# apollo3p register map
Vendor: Ambiq Micro; Series: Apollo; File version: 1.0
CPU: CM4 r1p0, little endian, MPU, FPU, I-cache, D-cache, VTOR, ITCM, DTCM, 3 interrupt priority bits, 0 interrupts
Registers are 32-bit, read-write, reset 0x0 unless marked. A register's access mark holds for its fields unless they carry their own. Offsets are from the block's base; [hi:lo] are bit positions; {n}, {i} and the like mark numbered series; 'fields as' and 'values as' point back to an identical list.

## CTIMER (part 3 of 3) — Counter/Timer
Base 0x40008000
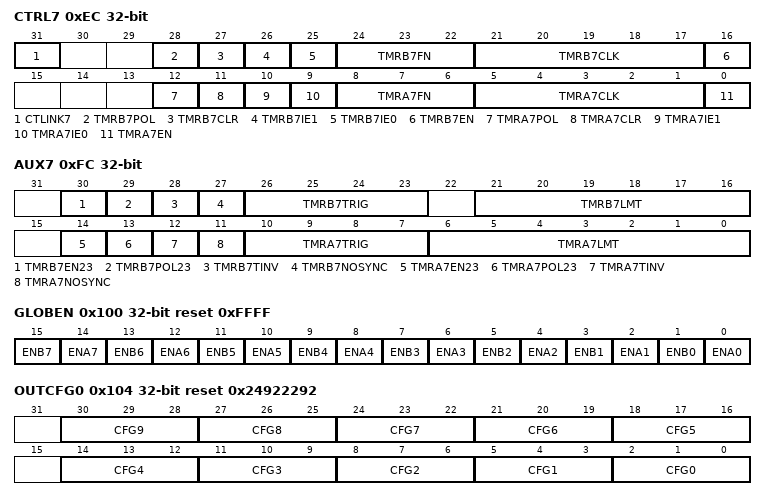
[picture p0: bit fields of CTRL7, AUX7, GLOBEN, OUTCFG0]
0xEC CTRL7 — This register holds the control bit fields for both halves of timer 7.
  [31] CTLINK7 — Counter/Timer A7/B7 Link bit.
    0=TWO_16BIT_TIMERS (Use A7/B7 timers as two independent 16-bit timers (default).); 1=32BIT_TIMER (Link A7/B7 timers into a single 32-bit timer.)
  [28] TMRB7POL — Counter/Timer B7 output polarity.
    0=NORMAL (The polarity of the TMRPINB7 pin is the same as the timer output.); 1=INVERTED (The polarity of the TMRPINB7 pin is the inverse of the timer output.)
  [27] TMRB7CLR — Counter/Timer B7 Clear bit.
    0=RUN (Allow counter/timer B7 to run); 1=CLEAR (Holds counter/timer B7 at 0x0000.)
  [26] TMRB7IE1 — Counter/Timer B7 Interrupt Enable bit for COMPR1.
    0=DIS (Disable counter/timer B7 from generating an interrupt based on COMPR1.); 1=EN (Enable counter/timer B7 to generate an interrupt based on COMPR1.)
  [25] TMRB7IE0 — Counter/Timer B7 Interrupt Enable bit for COMPR0.
    0=DIS (Disable counter/timer B7 from generating an interrupt based on COMPR0.); 1=EN (Enable counter/timer B7 to generate an interrupt based on COMPR0)
  [24:22] TMRB7FN — Counter/Timer B7 Function Select.
    0=SINGLECOUNT (Single count (output toggles and sticks). Count to CMPR0B7, stop.); 1=REPEATEDCOUNT (Repeated count (periodic 1-clock-cycle-wide pulses). Count to CMPR0B7, restart.); 2=PULSE_ONCE (Pulse once (aka one-shot). Count to CMPR0B7, assert, count to CMPR1B7, deassert, stop.); 3=PULSE_CONT (Pulse continuously. Count to CMPR0B7, assert, count to CMPR1B7, deassert, restart.); 4=SINGLEPATTERN; 5=REPEATPATTERN (Repeated pattern.); 6=CONTINUOUS (Continuous run (aka Free Run). Count continuously.); 7=ALTPWN (Alternate PWM)
  [21:17] TMRB7CLK — Counter/Timer B7 Clock Select.
    0=TMRPIN (Clock source is TMRPINB.); 1=HFRC_DIV4 (Clock source is the HFRC / 4); 2=HFRC_DIV16 (Clock source is HFRC / 16); 3=HFRC_DIV256 (Clock source is HFRC / 256); 4=HFRC_DIV1024 (Clock source is HFRC / 1024); 5=HFRC_DIV4K (Clock source is HFRC / 4096); 6=XT (Clock source is the XT (uncalibrated).); 7=XT_DIV2 (Clock source is XT / 2); 8=XT_DIV16 (Clock source is XT / 16); 9=XT_DIV128 (Clock source is XT / 128); 10=LFRC_DIV2 (Clock source is LFRC / 2); 11=LFRC_DIV32 (Clock source is LFRC / 32); 12=LFRC_DIV1K (Clock source is LFRC / 1024); 13=LFRC (Clock source is LFRC); 14=RTC_100HZ (Clock source is 100 Hz from the current RTC oscillator.); 15=HCLK_DIV4 (Clock source is HCLK / 4 (note: this clock is only available when MCU is in active mode)); 16=XT_DIV4 (Clock source is XT / 4); 17=XT_DIV8 (Clock source is XT / 8); 18=XT_DIV32 (Clock source is XT / 32); 20=CTMRA7 (Clock source is CTIMERA7 OUT.); 21=CTMRA2 (Clock source is CTIMERA2 OUT.); 22=CTMRB2 (Clock source is CTIMERB2 OUT.); 23=CTMRA0 (Clock source is CTIMERA0 OUT.); 24=CTMRB0 (Clock source is CTIMERB0 OUT.); 25=CTMRB1 (Clock source is CTIMERB1 OUT.); 26=CTMRB3 (Clock source is CTIMERB3 OUT.); 27=CTMRB4 (Clock source is CTIMERB4 OUT.); 28=CTMRB5 (Clock source is CTIMERB5 OUT.); 29=BUCKBLE (Clock source is BLE buck converter TON pulses.); 30=BUCKB (Clock source is Memory buck converter TON pulses.); 31=BUCKA (Clock source is CPU buck converter TON pulses.)
  [16] TMRB7EN — Counter/Timer B7 Enable bit.
    0=DIS (Counter/Timer B7 Disable.); 1=EN (Counter/Timer B7 Enable.)
  [12] TMRA7POL — Counter/Timer A7 output polarity.
    0=NORMAL (The polarity of the TMRPINA7 pin is the same as the timer output.); 1=INVERTED (The polarity of the TMRPINA7 pin is the inverse of the timer output.)
  [11] TMRA7CLR — Counter/Timer A7 Clear bit.
    0=RUN (Allow counter/timer A7 to run); 1=CLEAR (Holds counter/timer A7 at 0x0000.)
  [10] TMRA7IE1 — Counter/Timer A7 Interrupt Enable bit based on COMPR1.
    0=DIS (Disable counter/timer A7 from generating an interrupt based on COMPR1.); 1=EN (Enable counter/timer A7 to generate an interrupt based on COMPR1.)
  [9] TMRA7IE0 — Counter/Timer A7 Interrupt Enable bit based on COMPR0.
    0=DIS (Disable counter/timer A7 from generating an interrupt based on COMPR0.); 1=EN (Enable counter/timer A7 to generate an interrupt based on COMPR0.)
  [8:6] TMRA7FN — Counter/Timer A7 Function Select.
    0=SINGLECOUNT (Single count (output toggles and sticks). Count to CMPR0A7, stop.); 1=REPEATEDCOUNT (Repeated count (periodic 1-clock-cycle-wide pulses). Count to CMPR0A7, restart.); 2=PULSE_ONCE (Pulse once (aka one-shot). Count to CMPR0A7, assert, count to CMPR1A7, deassert, stop.); 3=PULSE_CONT (Pulse continuously. Count to CMPR0A7, assert, count to CMPR1A7, deassert, restart.); 4=SINGLEPATTERN; 5=REPEATPATTERN (Repeated pattern.); 6=CONTINUOUS (Continuous run (aka Free Run). Count continuously.); 7=ALTPWN (Alternate PWM)
  [5:1] TMRA7CLK — Counter/Timer A7 Clock Select.
    0=TMRPIN (Clock source is TMRPINA.); 1=HFRC_DIV4 (Clock source is the HFRC / 4); 2=HFRC_DIV16 (Clock source is HFRC / 16); 3=HFRC_DIV256 (Clock source is HFRC / 256); 4=HFRC_DIV1024 (Clock source is HFRC / 1024); 5=HFRC_DIV4K (Clock source is HFRC / 4096); 6=XT (Clock source is the XT (uncalibrated).); 7=XT_DIV2 (Clock source is XT / 2); 8=XT_DIV16 (Clock source is XT / 16); 9=XT_DIV128 (Clock source is XT / 128); 10=LFRC_DIV2 (Clock source is LFRC / 2); 11=LFRC_DIV32 (Clock source is LFRC / 32); 12=LFRC_DIV1K (Clock source is LFRC / 1024); 13=LFRC (Clock source is LFRC); 14=RTC_100HZ (Clock source is 100 Hz from the current RTC oscillator.); 15=HCLK_DIV4 (Clock source is HCLK / 4 (note: this clock is only available when MCU is in active mode)); 16=XT_DIV4 (Clock source is XT / 4); 17=XT_DIV8 (Clock source is XT / 8); 18=XT_DIV32 (Clock source is XT / 32); 20=CTMRB7 (Clock source is CTIMERB7 OUT.); 21=CTMRA2 (Clock source is CTIMERA2 OUT.); 22=CTMRB2 (Clock source is CTIMERB2 OUT.); 23=CTMRA0 (Clock source is CTIMERA0 OUT.); 24=CTMRB0 (Clock source is CTIMERB0 OUT.); 25=CTMRB1 (Clock source is CTIMERB1 OUT.); 26=CTMRB3 (Clock source is CTIMERB3 OUT.); 27=CTMRB4 (Clock source is CTIMERB4 OUT.); 28=CTMRB5 (Clock source is CTIMERB5 OUT.); 29=BUCKBLE (Clock source is BLE buck converter TON pulses.); 30=BUCKB (Clock source is Memory buck converter TON pulses.); 31=BUCKA (Clock source is CPU buck converter TON pulses.)
  [0] TMRA7EN — Counter/Timer A7 Enable bit.
    0=DIS (Counter/Timer A7 Disable.); 1=EN (Counter/Timer A7 Enable.)
0xFC AUX7 — Control bit fields for both halves of timer 0.
  [30] TMRB7EN23 — Counter/Timer B7 Upper compare enable.
    1=DIS (Disable enhanced functions.); 0=EN (Enable enhanced functions.)
  [29] TMRB7POL23 — Upper output polarity
    0=NORM (Upper output normal polarity); 1=INV (Upper output inverted polarity.)
  [28] TMRB7TINV — Counter/Timer B7 Invert on trigger.
    0=DIS (Disable invert on trigger); 1=EN (Enable invert on trigger)
  [27] TMRB7NOSYNC — Source clock synchronization control.
    0=DIS (Synchronization on source clock); 1=NOSYNC (No synchronization on source clock)
  [26:23] TMRB7TRIG — Counter/Timer B7 Trigger Select.
    0=DIS (Trigger source is disabled.); 1=A7OUT (Trigger source is CTIMERA7 OUT.); 2=B3OUT (Trigger source is CTIMERB3 OUT.); 3=A3OUT (Trigger source is CTIMERA3 OUT.); 4=A5OUT (Trigger source is CTIMERA5 OUT.); 5=B5OUT (Trigger source is CTIMERB5 OUT.); 6=A2OUT (Trigger source is CTIMERA2 OUT.); 7=B2OUT (Trigger source is CTIMERB2 OUT.); 8=B3OUT2 (Trigger source is CTIMERB3 OUT2.); 9=A3OUT2 (Trigger source is CTIMERA3 OUT2.); 10=A2OUT2 (Trigger source is CTIMERA2 OUT2.); 11=B2OUT2 (Trigger source is CTIMERB2 OUT2.); 12=A6OUT2DUAL (Trigger source is CTIMERA6 OUT2, dual edge.); 13=A7OUT2DUAL (Trigger source is CTIMERA7 OUT2, dual edge.); 14=B1OUT2DUAL (Trigger source is CTIMERB1 OUT2, dual edge.); 15=A1OUT2DUAL (Trigger source is CTIMERA1 OUT2, dual edge.)
  [21:16] TMRB7LMT — Counter/Timer B7 Pattern Limit Count.
  [14] TMRA7EN23 — Counter/Timer A7 Upper compare enable.
    values as TMRB7EN23
  [13] TMRA7POL23 — Counter/Timer A7 Upper output polarity
    values as TMRB7POL23
  [12] TMRA7TINV — Counter/Timer A7 Invert on trigger.
    values as TMRB7TINV
  [11] TMRA7NOSYNC — Source clock synchronization control.
    values as TMRB7NOSYNC
  [10:7] TMRA7TRIG — Counter/Timer A7 Trigger Select.
    0=DIS (Trigger source is disabled.); 1=B7OUT (Trigger source is CTIMERB7 OUT.); 2=B3OUT (Trigger source is CTIMERB3 OUT.); 3=A3OUT (Trigger source is CTIMERA3 OUT.); 4=A1OUT (Trigger source is CTIMERA1 OUT.); 5=B1OUT (Trigger source is CTIMERB1 OUT.); 6=A4OUT (Trigger source is CTIMERA4 OUT.); 7=B4OUT (Trigger source is CTIMERB4 OUT.); 8=B3OUT2 (Trigger source is CTIMERB3 OUT2.); 9=A3OUT2 (Trigger source is CTIMERA3 OUT2.); 10=A2OUT2 (Trigger source is CTIMERA2 OUT2.); 11=B2OUT2 (Trigger source is CTIMERB2 OUT2.); 12=A6OUT2DUAL (Trigger source is CTIMERA6 OUT2, dual edge.); 13=A5OUT2DUAL (Trigger source is CTIMERA5 OUT2, dual edge.); 14=B4OUT2DUAL (Trigger source is CTIMERB4 OUT2, dual edge.); 15=A4OUT2DUAL (Trigger source is CTIMERA4 OUT2, dual edge.)
  [6:0] TMRA7LMT — Counter/Timer A7 Pattern Limit Count.
0x100 GLOBEN reset 0xFFFF — Alternate enables for all CTIMERs.
  [all] fields
    1=LCO (Use local enable.); 0=DIS (Disable CTIMER.)
  [15] ENB7 — Alternate enable for B7.
  [2n] ENA{n} (n=0..7) — Alternate enable for A{n}
  [13] ENB6 — Alternate enable for B6
  [11] ENB5 — Alternate enable for B5
  [9] ENB4 — Alternate enable for B4
  [7] ENB3 — Alternate enable for B3.
  [5] ENB2 — Alternate enable for B2
  [3] ENB1 — Alternate enable for B1
  [1] ENB0 — Alternate enable for B0
0x104 OUTCFG0 reset 0x24922292 — Pad output configuration 0.
  [30:28] CFG9 — Pad output 9 configuration
    7=A7OUT2 (Output is A7OUT2.); 6=A6OUT2 (Output is A6OUT2.); 5=B0OUT (Output is B0OUT.); 4=A4OUT (Output is A4OUT.); 3=A2OUT (Output is A2OUT.); 2=A2OUT2 (Output is A2OUT2); 1=ONE (Force output to 1.); 0=ZERO (Force output to 0)
  [27:25] CFG8 — Pad output 8 configuration
    7=A7OUT2 (Output is A7OUT2.); 6=A6OUT2 (Output is A6OUT2.); 5=B6OUT (Output is B6OUT.); 4=A4OUT2 (Output is A4OUT2.); 3=A3OUT2 (Output is A3OUT.); 2=A2OUT (Output is A2OUT); 1=ONE (Force output to 1.); 0=ZERO (Force output to 0)
  [24:22] CFG7 — Pad output 7 configuration
    7=A7OUT2 (Output is A7OUT2.); 6=A6OUT2 (Output is A6OUT2.); 5=A7OUT (Output is A7OUT.); 4=B5OUT (Output is B5OUT.); 3=B1OUT (Output is B1OUT.); 2=B1OUT2 (Output is B1OUT2); 1=ONE (Force output to 1.); 0=ZERO (Force output to 0)
  [21:19] CFG6 — Pad output 6 configuration
    7=A7OUT2 (Output is A7OUT2.); 6=A6OUT2 (Output is A6OUT2.); 5=B7OUT (Output is B7OUT.); 4=B5OUT2 (Output is B5OUT2.); 3=A1OUT (Output is A1OUT.); 2=B1OUT (Output is B1OUT); 1=ONE (Force output to 1.); 0=ZERO (Force output to 0)
  [18:16] CFG5 — Pad output 5 configuration
    7=A7OUT2 (Output is A7OUT2.); 6=A6OUT2 (Output is A6OUT2.); 5=A7OUT (Output is A7OUT.); 4=B6OUT (Output is A5OUT.); 3=A1OUT (Output is A1OUT.); 2=A1OUT2 (Output is A1OUT2); 1=ONE (Force output to 1.); 0=ZERO (Force output to 0)
  [14:12] CFG4 — Pad output 4 configuration
    7=A7OUT2 (Output is A7OUT2.); 6=A6OUT2 (Output is A6OUT2.); 5=B5OUT (Output is B5OUT.); 4=A5OUT2 (Output is A5OUT2.); 3=A2OUT2 (Output is A2OUT2.); 2=A1OUT (Output is A1OUT); 1=ONE (Force output to 1.); 0=ZERO (Force output to 0)
  [11:9] CFG3 — Pad output 3 configuration
    7=A7OUT2 (Output is A7OUT2.); 6=A6OUT2 (Output is A6OUT2.); 5=A6OUT (Output is A6OUT.); 4=A1OUT (Output is A1OUT.); 3=B0OUT (Output is B0OUT.); 2=B0OUT2 (Output is B0OUT2); 1=ONE (Force output to 1.); 0=ZERO (Force output to 0)
  [8:6] CFG2 — Pad output 2 configuration
    7=A7OUT2 (Output is A7OUT2.); 6=A6OUT2 (Output is A6OUT2.); 5=A7OUT (Output is A7OUT.); 4=B6OUT2 (Output is B6OUT2.); 3=B1OUT2 (Output is B1OUT2.); 2=B0OUT (Output is B0OUT); 1=ONE (Force output to 1.); 0=ZERO (Force output to 0)
  [5:3] CFG1 — Pad output 1 configuration
    7=A7OUT2 (Output is A7OUT2.); 6=A6OUT2 (Output is A6OUT2.); 5=B7OUT2 (Output is B7OUT2.); 4=A5OUT (Output is A5OUT.); 3=A0OUT (Output is A0OUT.); 2=A0OUT2 (Output is A0OUT2); 1=ONE (Force output to 1.); 0=ZERO (Force output to 0)
  [2:0] CFG0 — Pad output 0 configuration
    7=A7OUT2 (Output is A7OUT2.); 6=A6OUT2 (Output is A6OUT2.); 5=A6OUT (Output is A6OUT.); 4=A5OUT2 (Output is A5OUT2.); 3=B2OUT2 (Output is B2OUT2.); 2=A0OUT (Output is A0OUT); 1=ONE (Force output to 1.); 0=ZERO (Force output to 0)
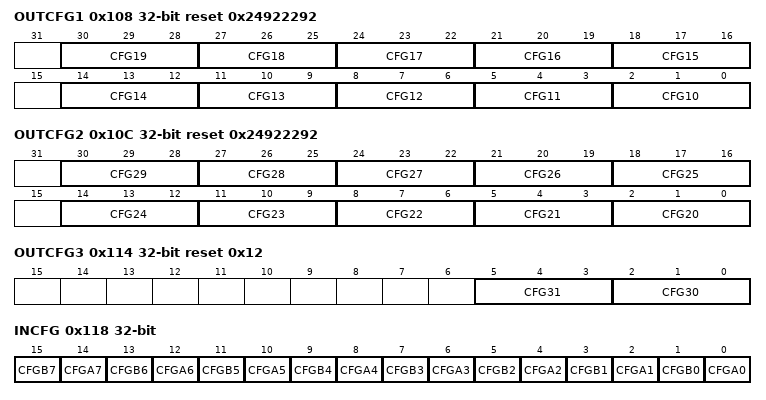
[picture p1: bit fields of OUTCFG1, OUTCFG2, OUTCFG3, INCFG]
0x108 OUTCFG1 reset 0x24922292 — Pad output configuration 1.
  [30:28] CFG19 — Pad output 19 configuration
    7=A7OUT2 (Output is A7OUT2.); 6=A6OUT2 (Output is A6OUT2.); 5=B1OUT2 (Output is B1OUT2.); 4=B4OUT (Output is B4OUT.); 3=A2OUT (Output is A2OUT.); 2=B4OUT2 (Output is B4OUT2); 1=ONE (Force output to 1.); 0=ZERO (Force output to 0)
  [27:25] CFG18 — Pad output 18 configuration
    7=A7OUT2 (Output is A7OUT2.); 6=A6OUT2 (Output is A6OUT2.); 5=A3OUT2 (Output is A3OUT2.); 4=A0OUT (Output is A0OUT.); 3=B0OUT (Output is B0OUT.); 2=B4OUT (Output is B4OUT); 1=ONE (Force output to 1.); 0=ZERO (Force output to 0)
  [24:22] CFG17 — Pad output 17 configuration
    7=A7OUT2 (Output is A7OUT2.); 6=A6OUT2 (Output is A6OUT2.); 5=A1OUT2 (Output is A1OUT2.); 4=A4OUT (Output is A4OUT.); 3=B7OUT (Output is B7OUT.); 2=A4OUT2 (Output is A4OUT2); 1=ONE (Force output to 1.); 0=ZERO (Force output to 0)
  [21:19] CFG16 — Pad output 16 configuration
    7=A7OUT2 (Output is A7OUT2.); 6=A6OUT2 (Output is A6OUT2.); 5=B3OUT2 (Output is B3OUT2.); 4=A0OUT2 (Output is A0OUT2.); 3=A0OUT (Output is A0OUT.); 2=A4OUT (Output is A4OUT); 1=ONE (Force output to 1.); 0=ZERO (Force output to 0)
  [18:16] CFG15 — Pad output 15 configuration
    7=A7OUT2 (Output is A7OUT2.); 6=A6OUT2 (Output is A6OUT2.); 5=A4OUT2 (Output is A4OUT2.); 4=A7OUT (Output is A7OUT.); 3=B3OUT (Output is B3OUT.); 2=B3OUT2 (Output is B3OUT2); 1=ONE (Force output to 1.); 0=ZERO (Force output to 0)
  [14:12] CFG14 — Pad output 14 configuration
    7=A7OUT2 (Output is A7OUT2.); 6=A6OUT2 (Output is A6OUT2.); 5=A7OUT (Output is A7OUT.); 4=B7OUT2 (Output is B7OUT2.); 3=B1OUT (Output is B1OUT.); 2=B3OUT (Output is B3OUT); 1=ONE (Force output to 1.); 0=ZERO (Force output to 0)
  [11:9] CFG13 — Pad output 13 configuration
    7=A7OUT2 (Output is A7OUT2.); 6=A6OUT2 (Output is A6OUT2.); 5=B4OUT2 (Output is B4OUT2.); 4=A6OUT (Output is A6OUT.); 3=A3OUT (Output is A3OUT.); 2=A3OUT2 (Output is A3OUT2); 1=ONE (Force output to 1.); 0=ZERO (Force output to 0)
  [8:6] CFG12 — Pad output 12 configuration
    7=A7OUT2 (Output is A7OUT2.); 6=A6OUT2 (Output is A6OUT2.); 5=B6OUT2 (Output is B6OUT2.); 4=B0OUT2 (Output is B0OUT2.); 3=B1OUT (Output is B1OUT.); 2=A3OUT (Output is A3OUT); 1=ONE (Force output to 1.); 0=ZERO (Force output to 0)
  [5:3] CFG11 — Pad output 11 configuration
    7=A7OUT2 (Output is A7OUT2.); 6=A6OUT2 (Output is A6OUT2.); 5=B5OUT2 (Output is B5OUT2.); 4=B4OUT (Output is B4OUT.); 3=B2OUT (Output is B2OUT.); 2=B2OUT2 (Output is B2OUT2); 1=ONE (Force output to 1.); 0=ZERO (Force output to 0)
  [2:0] CFG10 — Pad output 10 configuration
    7=A7OUT2 (Output is A7OUT2.); 6=A6OUT2 (Output is A6OUT2.); 5=A6OUT (Output is A6OUT.); 4=B4OUT2 (Output is B4OUT2.); 3=B3OUT2 (Output is B3OUT2.); 2=B2OUT (Output is B2OUT); 1=ONE (Force output to 1.); 0=ZERO (Force output to 0)
0x10C OUTCFG2 reset 0x24922292 — Pad output configuration 2.
  [30:28] CFG29 — Pad output 29 configuration
    7=A7OUT2 (Output is A7OUT2.); 6=A6OUT2 (Output is A6OUT2.); 5=A3OUT2 (Output is A3OUT2.); 4=A7OUT (Output is A7OUT.); 3=A1OUT (Output is A1OUT.); 2=B5OUT2 (Output is B5OUT2); 1=ONE (Force output to 1.); 0=ZERO (Force output to 0)
  [27:25] CFG28 — Pad output 28 configuration
    7=A7OUT2 (Output is A7OUT2.); 6=A6OUT2 (Output is A6OUT2.); 5=B0OUT2 (Output is B0OUT2.); 4=A5OUT2 (Output is A5OUT2.); 3=A3OUT (Output is A3OUT.); 2=A7OUT (Output is A7OUT); 1=ONE (Force output to 1.); 0=ZERO (Force output to 0)
  [24:22] CFG27 — Pad output 27 configuration
    7=A7OUT2 (Output is A7OUT2.); 6=A6OUT2 (Output is A6OUT2.); 5=B2OUT2 (Output is B2OUT2.); 4=B6OUT (Output is B6OUT.); 3=A1OUT (Output is A1OUT.); 2=B6OUT2 (Output is B6OUT2); 1=ONE (Force output to 1.); 0=ZERO (Force output to 0)
  [21:19] CFG26 — Pad output 26 configuration
    7=A7OUT2 (Output is A7OUT2.); 6=A6OUT2 (Output is A6OUT2.); 5=A1OUT2 (Output is A1OUT2.); 4=A5OUT (Output is A5OUT.); 3=B2OUT (Output is B2OUT.); 2=B6OUT (Output is B6OUT); 1=ONE (Force output to 1.); 0=ZERO (Force output to 0)
  [18:16] CFG25 — Pad output 25 configuration
    7=A7OUT2 (Output is A7OUT2.); 6=A6OUT2 (Output is A6OUT2.); 5=A2OUT2 (Output is A2OUT2.); 4=A6OUT (Output is A6OUT.); 3=B2OUT (Output is B2OUT.); 2=B4OUT2 (Output is B4OUT2); 1=ONE (Force output to 1.); 0=ZERO (Force output to 0)
  [14:12] CFG24 — Pad output 24 configuration
    7=A7OUT2 (Output is A7OUT2.); 6=A6OUT2 (Output is A6OUT2.); 5=B1OUT2 (Output is B1OUT2.); 4=A1OUT (Output is A1OUT.); 3=A2OUT (Output is A2OUT.); 2=A6OUT (Output is A6OUT); 1=ONE (Force output to 1.); 0=ZERO (Force output to 0)
  [11:9] CFG23 — Pad output 23 configuration
    7=A7OUT2 (Output is A7OUT2.); 6=A6OUT2 (Output is A6OUT2.); 5=B0OUT2 (Output is B0OUT2.); 4=A5OUT (Output is A5OUT.); 3=A7OUT (Output is A7OUT.); 2=B5OUT2 (Output is B5OUT2); 1=ONE (Force output to 1.); 0=ZERO (Force output to 0)
  [8:6] CFG22 — Pad output 22 configuration
    7=A7OUT2 (Output is A7OUT2.); 6=A6OUT2 (Output is A6OUT2.); 5=A2OUT2 (Output is A2OUT2.); 4=A1OUT (Output is A1OUT.); 3=A6OUT (Output is A6OUT.); 2=B5OUT (Output is B5OUT); 1=ONE (Force output to 1.); 0=ZERO (Force output to 0)
  [5:3] CFG21 — Pad output 21 configuration
    7=A7OUT2 (Output is A7OUT2.); 6=A6OUT2 (Output is A6OUT2.); 5=A0OUT2 (Output is A0OUT2.); 4=B5OUT (Output is B5OUT.); 3=A1OUT (Output is A1OUT.); 2=A5OUT2 (Output is A5OUT2); 1=ONE (Force output to 1.); 0=ZERO (Force output to 0)
  [2:0] CFG20 — Pad output 20 configuration
    7=A7OUT2 (Output is A7OUT2.); 6=A6OUT2 (Output is A6OUT2.); 5=B2OUT2 (Output is B2OUT2.); 4=A1OUT2 (Output is A1OUT2.); 3=A1OUT (Output is A1OUT.); 2=A5OUT (Output is A5OUT); 1=ONE (Force output to 1.); 0=ZERO (Force output to 0)
0x114 OUTCFG3 reset 0x12 — Pad output configuration 3.
  [5:3] CFG31 — Pad output 31 configuration
    7=A7OUT2 (Output is A7OUT2.); 6=A6OUT2 (Output is A6OUT2.); 5=B3OUT2 (Output is B3OUT2.); 4=B7OUT (Output is B7OUT.); 3=A6OUT (Output is A6OUT.); 2=B7OUT2 (Output is B7OUT2); 1=ONE (Force output to 1.); 0=ZERO (Force output to 0)
  [2:0] CFG30 — Pad output 30 configuration
    7=A7OUT2 (Output is A7OUT2.); 6=A6OUT2 (Output is A6OUT2.); 5=A0OUT2 (Output is A0OUT2.); 4=A4OUT2 (Output is A4OUT2.); 3=B3OUT (Output is B3OUT.); 2=B7OUT (Output is B7OUT); 1=ONE (Force output to 1.); 0=ZERO (Force output to 0)
0x118 INCFG — Pad input configuration.
  [2n+1] CFGB{n} (n=0..7) — CTIMER B{n} input configuration
    1=CT{4n+3} (Input is CT{4n+3}); 0=CT{4n+2} (Input is CT{4n+2})
  [2n] CFGA{n} (n=0..7) — CTIMER A{n} input configuration
    1=CT{4n+1} (Input is CT{4n+1}); 0=CT{4n} (Input is CT{4n})
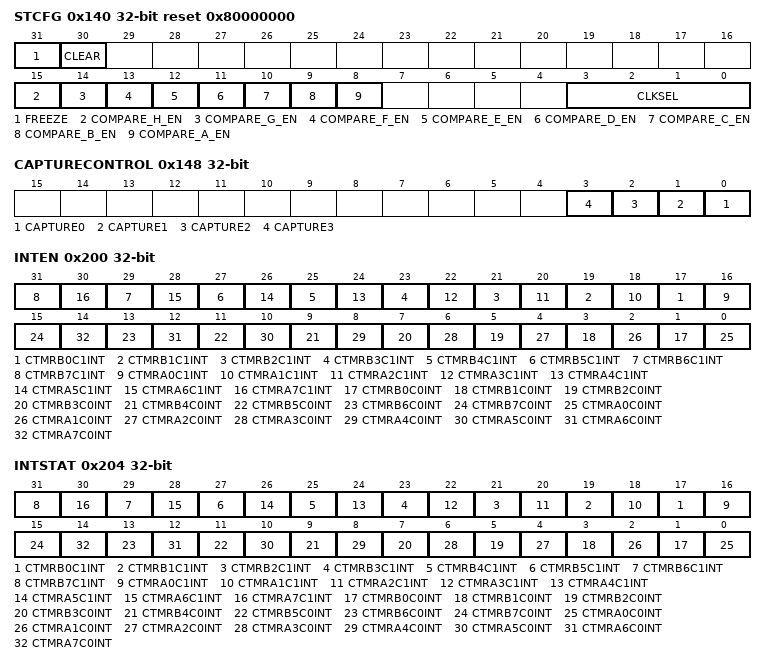
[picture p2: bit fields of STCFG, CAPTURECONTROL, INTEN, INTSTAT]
0x140 STCFG reset 0x80000000 — The STIMER Configuration Register contains the software control for selecting the clock divider and source feeding the system timer.
  [31] FREEZE — Set this bit to one to freeze the clock input to the COUNTER register. Once frozen, the value can be safely written from the MCU. Unfreeze to resume.
    0=THAW (Let the COUNTER register run on its input clock.); 1=FREEZE (Stop the COUNTER register for loading.)
  [30] CLEAR — Set this bit to one to clear the System Timer register. If this bit is set to '1', the system timer register will stay cleared. It needs to be set to '0' for the system timer to start running.
    0=RUN (Let the COUNTER register run on its input clock.); 1=CLEAR (Stop the COUNTER register for loading.)
  [15] COMPARE_H_EN — Selects whether compare is enabled for the corresponding SCMPR register. If compare is enabled, the interrupt status is set once the comparison is met.
    0=DISABLE (Compare H disabled.); 1=ENABLE (Compare H enabled.)
  [14] COMPARE_G_EN — Selects whether compare is enabled for the corresponding SCMPR register. If compare is enabled, the interrupt status is set once the comparison is met.
    0=DISABLE (Compare G disabled.); 1=ENABLE (Compare G enabled.)
  [13] COMPARE_F_EN — Selects whether compare is enabled for the corresponding SCMPR register. If compare is enabled, the interrupt status is set once the comparison is met.
    0=DISABLE (Compare F disabled.); 1=ENABLE (Compare F enabled.)
  [12] COMPARE_E_EN — Selects whether compare is enabled for the corresponding SCMPR register. If compare is enabled, the interrupt status is set once the comparison is met.
    0=DISABLE (Compare E disabled.); 1=ENABLE (Compare E enabled.)
  [11] COMPARE_D_EN — Selects whether compare is enabled for the corresponding SCMPR register. If compare is enabled, the interrupt status is set once the comparison is met.
    0=DISABLE (Compare D disabled.); 1=ENABLE (Compare D enabled.)
  [10] COMPARE_C_EN — Selects whether compare is enabled for the corresponding SCMPR register. If compare is enabled, the interrupt status is set once the comparison is met.
    0=DISABLE (Compare C disabled.); 1=ENABLE (Compare C enabled.)
  [9] COMPARE_B_EN — Selects whether compare is enabled for the corresponding SCMPR register. If compare is enabled, the interrupt status is set once the comparison is met.
    0=DISABLE (Compare B disabled.); 1=ENABLE (Compare B enabled.)
  [8] COMPARE_A_EN — Selects whether compare is enabled for the corresponding SCMPR register. If compare is enabled, the interrupt status is set once the comparison is met.
    0=DISABLE (Compare A disabled.); 1=ENABLE (Compare A enabled.)
  [3:0] CLKSEL — Selects an appropriate clock source and divider to use for the System Timer clock.
    0=NOCLK (No clock enabled.); 1=HFRC_DIV16 (3MHz from the HFRC clock divider.); 2=HFRC_DIV256 (187.5KHz from the HFRC clock divider.); 3=XTAL_DIV1 (32768Hz from the crystal oscillator.); 4=XTAL_DIV2 (16384Hz from the crystal oscillator.); 5=XTAL_DIV32 (1024Hz from the crystal oscillator.); 6=LFRC_DIV1 (Approximately 1KHz from the LFRC oscillator (uncalibrated).); 7=CTIMER0A (Use CTIMER 0 section A as a prescaler for the clock source.); 8=CTIMER0B (Use CTIMER 0 section B (or A and B linked together) as a prescaler for the clock source.)
0x144 STTMR — The COUNTER Register contains the running count of time as maintained by incrementing for every rising clock edge of the clock source selected in the configuration register. It is this counter value that captured in the capture registers and it is this counter value that is compared against the various compare registers. This register cannot be written, but can be cleared to 0 for a deterministic value. Use the FREEZE bit will stop this counter from incrementing.
  [31:0] STTMR — Value of the 32-bit counter as it ticks over.
0x148 CAPTURECONTROL — The STIMER Capture Control Register controls each of the 4 capture registers. It selects their GPIO pin number for a trigger source, enables a capture operation and sets the input polarity for the capture. NOTE: 8-bit writes can control individual capture registers atomically.
  [all] fields
    0=DISABLE (Capture function disabled.); 1=ENABLE (Capture function enabled.)
  [n] CAPTURE{n} (n=0..3) — Selects whether capture is enabled for the specified capture register.
0x150 SCMPR0 — The VALUE in this bit field is used to compare against the VALUE in the COUNTER register. If the match criterion in the configuration register is met then a corresponding interrupt status bit is set. The match criterion is defined as COUNTER equal to COMPARE. To establish a desired value in this COMPARE register, write the number of ticks in the future to this register to indicate when to interrupt. The hardware does the addition to the COUNTER value in the STIMER clock domain so that the math is precise. Reading this register shows the COUNTER value at which this interrupt will occur.
  [31:0] SCMPR0 — Compare this value to the value in the COUNTER register according to the match criterion, as selected in the COMPARE_A_EN bit in the REG_CTIMER_STCGF register.
0x154 SCMPR1 — The VALUE in this bit field is used to compare against the VALUE in the COUNTER register. If the match criterion in the configuration register is met then a corresponding interrupt status bit is set. The match criterion is defined as COUNTER equal to COMPARE. To establish a desired value in this COMPARE register, write the number of ticks in the future to this register to indicate when to interrupt. The hardware does the addition to the COUNTER value in the STIMER clock domain so that the math is precise. Reading this register shows the COUNTER value at which this interrupt will occur.
  [31:0] SCMPR1 — Compare this value to the value in the COUNTER register according to the match criterion, as selected in the COMPARE_B_EN bit in the REG_CTIMER_STCGF register.
0x158 SCMPR2 — The VALUE in this bit field is used to compare against the VALUE in the COUNTER register. If the match criterion in the configuration register is met then a corresponding interrupt status bit is set. The match criterion is defined as COUNTER equal to COMPARE. To establish a desired value in this COMPARE register, write the number of ticks in the future to this register to indicate when to interrupt. The hardware does the addition to the COUNTER value in the STIMER clock domain so that the math is precise. Reading this register shows the COUNTER value at which this interrupt will occur.
  [31:0] SCMPR2 — Compare this value to the value in the COUNTER register according to the match criterion, as selected in the COMPARE_C_EN bit in the REG_CTIMER_STCGF register.
0x15C SCMPR3 — The VALUE in this bit field is used to compare against the VALUE in the COUNTER register. If the match criterion in the configuration register is met then a corresponding interrupt status bit is set. The match criterion is defined as COUNTER equal to COMPARE. To establish a desired value in this COMPARE register, write the number of ticks in the future to this register to indicate when to interrupt. The hardware does the addition to the COUNTER value in the STIMER clock domain so that the math is precise. Reading this register shows the COUNTER value at which this interrupt will occur.
  [31:0] SCMPR3 — Compare this value to the value in the COUNTER register according to the match criterion, as selected in the COMPARE_D_EN bit in the REG_CTIMER_STCGF register.
0x160 SCMPR4 — The VALUE in this bit field is used to compare against the VALUE in the COUNTER register. If the match criterion in the configuration register is met then a corresponding interrupt status bit is set. The match criterion is defined as COUNTER equal to COMPARE. To establish a desired value in this COMPARE register, write the number of ticks in the future to this register to indicate when to interrupt. The hardware does the addition to the COUNTER value in the STIMER clock domain so that the math is precise. Reading this register shows the COUNTER value at which this interrupt will occur.
  [31:0] SCMPR4 — Compare this value to the value in the COUNTER register according to the match criterion, as selected in the COMPARE_E_EN bit in the REG_CTIMER_STCGF register.
0x164 SCMPR5 — The VALUE in this bit field is used to compare against the VALUE in the COUNTER register. If the match criterion in the configuration register is met then a corresponding interrupt status bit is set. The match criterion is defined as COUNTER equal to COMPARE. To establish a desired value in this COMPARE register, write the number of ticks in the future to this register to indicate when to interrupt. The hardware does the addition to the COUNTER value in the STIMER clock domain so that the math is precise. Reading this register shows the COUNTER value at which this interrupt will occur.
  [31:0] SCMPR5 — Compare this value to the value in the COUNTER register according to the match criterion, as selected in the COMPARE_F_EN bit in the REG_CTIMER_STCGF register.
0x168 SCMPR6 — The VALUE in this bit field is used to compare against the VALUE in the COUNTER register. If the match criterion in the configuration register is met then a corresponding interrupt status bit is set. The match criterion is defined as COUNTER equal to COMPARE. To establish a desired value in this COMPARE register, write the number of ticks in the future to this register to indicate when to interrupt. The hardware does the addition to the COUNTER value in the STIMER clock domain so that the math is precise. Reading this register shows the COUNTER value at which this interrupt will occur.
  [31:0] SCMPR6 — Compare this value to the value in the COUNTER register according to the match criterion, as selected in the COMPARE_G_EN bit in the REG_CTIMER_STCGF register.
0x16C SCMPR7 — The VALUE in this bit field is used to compare against the VALUE in the COUNTER register. If the match criterion in the configuration register is met then a corresponding interrupt status bit is set. The match criterion is defined as COUNTER equal to COMPARE. To establish a desired value in this COMPARE register, write the number of ticks in the future to this register to indicate when to interrupt. The hardware does the addition to the COUNTER value in the STIMER clock domain so that the math is precise.
  [31:0] SCMPR7 — Compare this value to the value in the COUNTER register according to the match criterion, as selected in the COMPARE_H_EN bit in the REG_CTIMER_STCGF register.
0x1E0 SCAPT0 — The STIMER Capture Register A grabs the VALUE in the COUNTER register whenever capture condition (event) A is asserted. This register holds a time stamp for the event.
  [31:0] SCAPT0 — Whenever the event is detected, the value in the COUNTER is copied into this register and the corresponding interrupt status bit is set.
0x1E4 SCAPT1 — The STIMER Capture Register B grabs the VALUE in the COUNTER register whenever capture condition (event) B is asserted. This register holds a time stamp for the event.
  [31:0] SCAPT1 — Whenever the event is detected, the value in the COUNTER is copied into this register and the corresponding interrupt status bit is set.
0x1E8 SCAPT2 — The STIMER Capture Register C grabs the VALUE in the COUNTER register whenever capture condition (event) C is asserted. This register holds a time stamp for the event.
  [31:0] SCAPT2 — Whenever the event is detected, the value in the COUNTER is copied into this register and the corresponding interrupt status bit is set.
0x1EC SCAPT3 — The STIMER Capture Register D grabs the VALUE in the COUNTER register whenever capture condition (event) D is asserted. This register holds a time stamp for the event.
  [31:0] SCAPT3 — Whenever the event is detected, the value in the COUNTER is copied into this register and the corresponding interrupt status bit is set.
0x1F0 SNVR0 — The NVRAM_A Register contains a portion of the stored epoch offset associated with the time in the COUNTER register. This register is only reset by POI not by HRESETn. Its contents are intended to survive all reset level except POI and full power cycles.
  [31:0] SNVR0 — Value of the 32-bit counter as it ticks over.
0x1F4 SNVR1 — The NVRAM_B Register contains a portion of the stored epoch offset associated with the time in the COUNTER register. This register is only reset by POI not by HRESETn. Its contents are intended to survive all reset level except POI and full power cycles.
  [31:0] SNVR1 — Value of the 32-bit counter as it ticks over.
0x1F8 SNVR2 — The NVRAM_C Register contains a portion of the stored epoch offset associated with the time in the COUNTER register. This register is only reset by POI not by HRESETn. Its contents are intended to survive all reset level except POI and full power cycles.
  [31:0] SNVR2 — Value of the 32-bit counter as it ticks over.
0x1FC SNVR3 — The NVRAM_D Register contains a portion of the stored epoch offset associated with the time in the COUNTER register. This register is only reset by POI not by HRESETn. Its contents are intended to survive all reset level except POI and full power cycles.
  [31:0] SNVR3 — Value of the 32-bit counter as it ticks over.
0x200 INTEN — Set bits in this register to allow this module to generate the corresponding interrupt.
  [2n+17] CTMRB{n}C1INT (n=0..7) — Counter/Timer B{n} interrupt based on COMPR1.
  [2n+16] CTMRA{n}C1INT (n=0..7) — Counter/Timer A{n} interrupt based on COMPR1.
  [2n+1] CTMRB{n}C0INT (n=0..7) — Counter/Timer B{n} interrupt based on COMPR0.
  [2n] CTMRA{n}C0INT (n=0..7) — Counter/Timer A{n} interrupt based on COMPR0.
0x204 INTSTAT — Read bits from this register to discover the cause of a recent interrupt.
  fields as INTEN
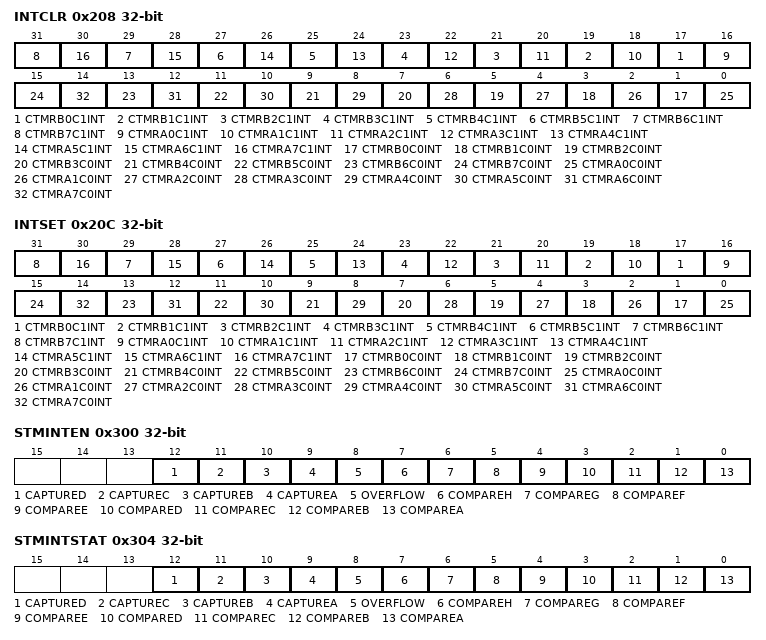
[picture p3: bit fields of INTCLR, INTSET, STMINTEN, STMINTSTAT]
0x208 INTCLR — Write a 1 to a bit in this register to clear the interrupt status associated with that bit.
  fields as INTEN
0x20C INTSET — Write a 1 to a bit in this register to instantly generate an interrupt from this module. (Generally used for testing purposes).
  fields as INTEN
0x300 STMINTEN — Set bits in this register to allow this module to generate the corresponding interrupt.
  [12] CAPTURED — CAPTURE register D has grabbed the value in the counter
    1=CAPD_INT (Capture D interrupt status bit was set.)
  [11] CAPTUREC — CAPTURE register C has grabbed the value in the counter
    1=CAPC_INT (CAPTURE C interrupt status bit was set.)
  [10] CAPTUREB — CAPTURE register B has grabbed the value in the counter
    1=CAPB_INT (CAPTURE B interrupt status bit was set.)
  [9] CAPTUREA — CAPTURE register A has grabbed the value in the counter
    1=CAPA_INT (CAPTURE A interrupt status bit was set.)
  [8] OVERFLOW — COUNTER over flowed from 0xFFFFFFFF back to 0x00000000.
    1=OFLOW_INT (Overflow interrupt status bit was set.)
  [7] COMPAREH — COUNTER is greater than or equal to COMPARE register H.
    1=COMPARED (COUNTER greater than or equal to COMPARE register.)
  [6] COMPAREG — COUNTER is greater than or equal to COMPARE register G.
    values as COMPAREH
  [5] COMPAREF — COUNTER is greater than or equal to COMPARE register F.
    values as COMPAREH
  [4] COMPAREE — COUNTER is greater than or equal to COMPARE register E.
    values as COMPAREH
  [3] COMPARED — COUNTER is greater than or equal to COMPARE register D.
    values as COMPAREH
  [2] COMPAREC — COUNTER is greater than or equal to COMPARE register C.
    values as COMPAREH
  [1] COMPAREB — COUNTER is greater than or equal to COMPARE register B.
    values as COMPAREH
  [0] COMPAREA — COUNTER is greater than or equal to COMPARE register A.
    values as COMPAREH
0x304 STMINTSTAT — Read bits from this register to discover the cause of a recent interrupt.
  fields as STMINTEN
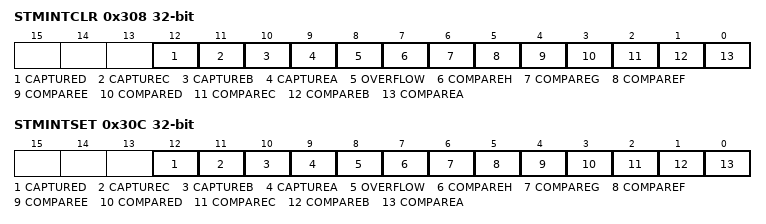
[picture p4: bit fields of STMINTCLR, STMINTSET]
0x308 STMINTCLR — Write a 1 to a bit in this register to clear the interrupt status associated with that bit.
  fields as STMINTEN
0x30C STMINTSET — Write a 1 to a bit in this register to instantly generate an interrupt from this module. (Generally used for testing purposes).
  fields as STMINTEN
